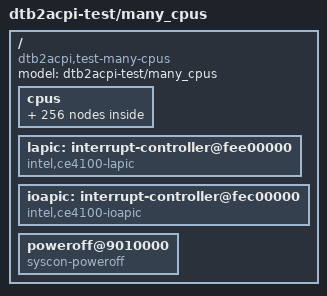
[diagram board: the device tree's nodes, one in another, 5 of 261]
/dts-v1/;

/* GENERATED by generate_many_cpus.sh — do not edit by hand. */

/ {
	#address-cells = <2>;
	#size-cells = <2>;
	model = "dtb2acpi-test/many_cpus";
	compatible = "dtb2acpi,test-many-cpus";

	cpus {
		#address-cells = <1>;
		#size-cells = <0>;

		cpu@0 {
			device_type = "cpu";
			reg = <0x0>;
			compatible = "intel,x86";
		};

		cpu@1 {
			device_type = "cpu";
			reg = <0x1>;
			compatible = "intel,x86";
		};

		cpu@2 {
			device_type = "cpu";
			reg = <0x2>;
			compatible = "intel,x86";
		};

		cpu@3 {
			device_type = "cpu";
			reg = <0x3>;
			compatible = "intel,x86";
		};

		cpu@4 {
			device_type = "cpu";
			reg = <0x4>;
			compatible = "intel,x86";
		};

		cpu@5 {
			device_type = "cpu";
			reg = <0x5>;
			compatible = "intel,x86";
		};

		cpu@6 {
			device_type = "cpu";
			reg = <0x6>;
			compatible = "intel,x86";
		};

		cpu@7 {
			device_type = "cpu";
			reg = <0x7>;
			compatible = "intel,x86";
		};

		cpu@8 {
			device_type = "cpu";
			reg = <0x8>;
			compatible = "intel,x86";
		};

		cpu@9 {
			device_type = "cpu";
			reg = <0x9>;
			compatible = "intel,x86";
		};

		cpu@a {
			device_type = "cpu";
			reg = <0xa>;
			compatible = "intel,x86";
		};

		cpu@b {
			device_type = "cpu";
			reg = <0xb>;
			compatible = "intel,x86";
		};

		cpu@c {
			device_type = "cpu";
			reg = <0xc>;
			compatible = "intel,x86";
		};

		cpu@d {
			device_type = "cpu";
			reg = <0xd>;
			compatible = "intel,x86";
		};

		cpu@e {
			device_type = "cpu";
			reg = <0xe>;
			compatible = "intel,x86";
		};

		cpu@f {
			device_type = "cpu";
			reg = <0xf>;
			compatible = "intel,x86";
		};

		cpu@10 {
			device_type = "cpu";
			reg = <0x10>;
			compatible = "intel,x86";
		};

		cpu@11 {
			device_type = "cpu";
			reg = <0x11>;
			compatible = "intel,x86";
		};

		cpu@12 {
			device_type = "cpu";
			reg = <0x12>;
			compatible = "intel,x86";
		};

		cpu@13 {
			device_type = "cpu";
			reg = <0x13>;
			compatible = "intel,x86";
		};

		cpu@14 {
			device_type = "cpu";
			reg = <0x14>;
			compatible = "intel,x86";
		};

		cpu@15 {
			device_type = "cpu";
			reg = <0x15>;
			compatible = "intel,x86";
		};

		cpu@16 {
			device_type = "cpu";
			reg = <0x16>;
			compatible = "intel,x86";
		};

		cpu@17 {
			device_type = "cpu";
			reg = <0x17>;
			compatible = "intel,x86";
		};

		cpu@18 {
			device_type = "cpu";
			reg = <0x18>;
			compatible = "intel,x86";
		};

		cpu@19 {
			device_type = "cpu";
			reg = <0x19>;
			compatible = "intel,x86";
		};

		cpu@1a {
			device_type = "cpu";
			reg = <0x1a>;
			compatible = "intel,x86";
		};

		cpu@1b {
			device_type = "cpu";
			reg = <0x1b>;
			compatible = "intel,x86";
		};

		cpu@1c {
			device_type = "cpu";
			reg = <0x1c>;
			compatible = "intel,x86";
		};

		cpu@1d {
			device_type = "cpu";
			reg = <0x1d>;
			compatible = "intel,x86";
		};

		cpu@1e {
			device_type = "cpu";
			reg = <0x1e>;
			compatible = "intel,x86";
		};

		cpu@1f {
			device_type = "cpu";
			reg = <0x1f>;
			compatible = "intel,x86";
		};

		cpu@20 {
			device_type = "cpu";
			reg = <0x20>;
			compatible = "intel,x86";
		};

		cpu@21 {
			device_type = "cpu";
			reg = <0x21>;
			compatible = "intel,x86";
		};

		cpu@22 {
			device_type = "cpu";
			reg = <0x22>;
			compatible = "intel,x86";
		};

		cpu@23 {
			device_type = "cpu";
			reg = <0x23>;
			compatible = "intel,x86";
		};

		cpu@24 {
			device_type = "cpu";
			reg = <0x24>;
			compatible = "intel,x86";
		};

		cpu@25 {
			device_type = "cpu";
			reg = <0x25>;
			compatible = "intel,x86";
		};

		cpu@26 {
			device_type = "cpu";
			reg = <0x26>;
			compatible = "intel,x86";
		};

		cpu@27 {
			device_type = "cpu";
			reg = <0x27>;
			compatible = "intel,x86";
		};

		cpu@28 {
			device_type = "cpu";
			reg = <0x28>;
			compatible = "intel,x86";
		};

		cpu@29 {
			device_type = "cpu";
			reg = <0x29>;
			compatible = "intel,x86";
		};

		cpu@2a {
			device_type = "cpu";
			reg = <0x2a>;
			compatible = "intel,x86";
		};

		cpu@2b {
			device_type = "cpu";
			reg = <0x2b>;
			compatible = "intel,x86";
		};

		cpu@2c {
			device_type = "cpu";
			reg = <0x2c>;
			compatible = "intel,x86";
		};

		cpu@2d {
			device_type = "cpu";
			reg = <0x2d>;
			compatible = "intel,x86";
		};

		cpu@2e {
			device_type = "cpu";
			reg = <0x2e>;
			compatible = "intel,x86";
		};

		cpu@2f {
			device_type = "cpu";
			reg = <0x2f>;
			compatible = "intel,x86";
		};

		cpu@30 {
			device_type = "cpu";
			reg = <0x30>;
			compatible = "intel,x86";
		};

		cpu@31 {
			device_type = "cpu";
			reg = <0x31>;
			compatible = "intel,x86";
		};

		cpu@32 {
			device_type = "cpu";
			reg = <0x32>;
			compatible = "intel,x86";
		};

		cpu@33 {
			device_type = "cpu";
			reg = <0x33>;
			compatible = "intel,x86";
		};

		cpu@34 {
			device_type = "cpu";
			reg = <0x34>;
			compatible = "intel,x86";
		};

		cpu@35 {
			device_type = "cpu";
			reg = <0x35>;
			compatible = "intel,x86";
		};

		cpu@36 {
			device_type = "cpu";
			reg = <0x36>;
			compatible = "intel,x86";
		};

		cpu@37 {
			device_type = "cpu";
			reg = <0x37>;
			compatible = "intel,x86";
		};

		cpu@38 {
			device_type = "cpu";
			reg = <0x38>;
			compatible = "intel,x86";
		};

		cpu@39 {
			device_type = "cpu";
			reg = <0x39>;
			compatible = "intel,x86";
		};

		cpu@3a {
			device_type = "cpu";
			reg = <0x3a>;
			compatible = "intel,x86";
		};

		cpu@3b {
			device_type = "cpu";
			reg = <0x3b>;
			compatible = "intel,x86";
		};

		cpu@3c {
			device_type = "cpu";
			reg = <0x3c>;
			compatible = "intel,x86";
		};

		cpu@3d {
			device_type = "cpu";
			reg = <0x3d>;
			compatible = "intel,x86";
		};

		cpu@3e {
			device_type = "cpu";
			reg = <0x3e>;
			compatible = "intel,x86";
		};

		cpu@3f {
			device_type = "cpu";
			reg = <0x3f>;
			compatible = "intel,x86";
		};

		cpu@40 {
			device_type = "cpu";
			reg = <0x40>;
			compatible = "intel,x86";
		};

		cpu@41 {
			device_type = "cpu";
			reg = <0x41>;
			compatible = "intel,x86";
		};

		cpu@42 {
			device_type = "cpu";
			reg = <0x42>;
			compatible = "intel,x86";
		};

		cpu@43 {
			device_type = "cpu";
			reg = <0x43>;
			compatible = "intel,x86";
		};

		cpu@44 {
			device_type = "cpu";
			reg = <0x44>;
			compatible = "intel,x86";
		};

		cpu@45 {
			device_type = "cpu";
			reg = <0x45>;
			compatible = "intel,x86";
		};

		cpu@46 {
			device_type = "cpu";
			reg = <0x46>;
			compatible = "intel,x86";
		};

		cpu@47 {
			device_type = "cpu";
			reg = <0x47>;
			compatible = "intel,x86";
		};

		cpu@48 {
			device_type = "cpu";
			reg = <0x48>;
			compatible = "intel,x86";
		};

		cpu@49 {
			device_type = "cpu";
			reg = <0x49>;
			compatible = "intel,x86";
		};

		cpu@4a {
			device_type = "cpu";
			reg = <0x4a>;
			compatible = "intel,x86";
		};

		cpu@4b {
			device_type = "cpu";
			reg = <0x4b>;
			compatible = "intel,x86";
		};

		cpu@4c {
			device_type = "cpu";
			reg = <0x4c>;
			compatible = "intel,x86";
		};

		cpu@4d {
			device_type = "cpu";
			reg = <0x4d>;
			compatible = "intel,x86";
		};

		cpu@4e {
			device_type = "cpu";
			reg = <0x4e>;
			compatible = "intel,x86";
		};

		cpu@4f {
			device_type = "cpu";
			reg = <0x4f>;
			compatible = "intel,x86";
		};

		cpu@50 {
			device_type = "cpu";
			reg = <0x50>;
			compatible = "intel,x86";
		};

		cpu@51 {
			device_type = "cpu";
			reg = <0x51>;
			compatible = "intel,x86";
		};

		cpu@52 {
			device_type = "cpu";
			reg = <0x52>;
			compatible = "intel,x86";
		};

		cpu@53 {
			device_type = "cpu";
			reg = <0x53>;
			compatible = "intel,x86";
		};

		cpu@54 {
			device_type = "cpu";
			reg = <0x54>;
			compatible = "intel,x86";
		};

		cpu@55 {
			device_type = "cpu";
			reg = <0x55>;
			compatible = "intel,x86";
		};

		cpu@56 {
			device_type = "cpu";
			reg = <0x56>;
			compatible = "intel,x86";
		};

		cpu@57 {
			device_type = "cpu";
			reg = <0x57>;
			compatible = "intel,x86";
		};

		cpu@58 {
			device_type = "cpu";
			reg = <0x58>;
			compatible = "intel,x86";
		};

		cpu@59 {
			device_type = "cpu";
			reg = <0x59>;
			compatible = "intel,x86";
		};

		cpu@5a {
			device_type = "cpu";
			reg = <0x5a>;
			compatible = "intel,x86";
		};

		cpu@5b {
			device_type = "cpu";
			reg = <0x5b>;
			compatible = "intel,x86";
		};

		cpu@5c {
			device_type = "cpu";
			reg = <0x5c>;
			compatible = "intel,x86";
		};

		cpu@5d {
			device_type = "cpu";
			reg = <0x5d>;
			compatible = "intel,x86";
		};

		cpu@5e {
			device_type = "cpu";
			reg = <0x5e>;
			compatible = "intel,x86";
		};

		cpu@5f {
			device_type = "cpu";
			reg = <0x5f>;
			compatible = "intel,x86";
		};

		cpu@60 {
			device_type = "cpu";
			reg = <0x60>;
			compatible = "intel,x86";
		};

		cpu@61 {
			device_type = "cpu";
			reg = <0x61>;
			compatible = "intel,x86";
		};

		cpu@62 {
			device_type = "cpu";
			reg = <0x62>;
			compatible = "intel,x86";
		};

		cpu@63 {
			device_type = "cpu";
			reg = <0x63>;
			compatible = "intel,x86";
		};

		cpu@64 {
			device_type = "cpu";
			reg = <0x64>;
			compatible = "intel,x86";
		};

		cpu@65 {
			device_type = "cpu";
			reg = <0x65>;
			compatible = "intel,x86";
		};

		cpu@66 {
			device_type = "cpu";
			reg = <0x66>;
			compatible = "intel,x86";
		};

		cpu@67 {
			device_type = "cpu";
			reg = <0x67>;
			compatible = "intel,x86";
		};

		cpu@68 {
			device_type = "cpu";
			reg = <0x68>;
			compatible = "intel,x86";
		};

		cpu@69 {
			device_type = "cpu";
			reg = <0x69>;
			compatible = "intel,x86";
		};

		cpu@6a {
			device_type = "cpu";
			reg = <0x6a>;
			compatible = "intel,x86";
		};

		cpu@6b {
			device_type = "cpu";
			reg = <0x6b>;
			compatible = "intel,x86";
		};

		cpu@6c {
			device_type = "cpu";
			reg = <0x6c>;
			compatible = "intel,x86";
		};

		cpu@6d {
			device_type = "cpu";
			reg = <0x6d>;
			compatible = "intel,x86";
		};

		cpu@6e {
			device_type = "cpu";
			reg = <0x6e>;
			compatible = "intel,x86";
		};

		cpu@6f {
			device_type = "cpu";
			reg = <0x6f>;
			compatible = "intel,x86";
		};

		cpu@70 {
			device_type = "cpu";
			reg = <0x70>;
			compatible = "intel,x86";
		};

		cpu@71 {
			device_type = "cpu";
			reg = <0x71>;
			compatible = "intel,x86";
		};

		cpu@72 {
			device_type = "cpu";
			reg = <0x72>;
			compatible = "intel,x86";
		};

		cpu@73 {
			device_type = "cpu";
			reg = <0x73>;
			compatible = "intel,x86";
		};

		cpu@74 {
			device_type = "cpu";
			reg = <0x74>;
			compatible = "intel,x86";
		};

		cpu@75 {
			device_type = "cpu";
			reg = <0x75>;
			compatible = "intel,x86";
		};

		cpu@76 {
			device_type = "cpu";
			reg = <0x76>;
			compatible = "intel,x86";
		};

		cpu@77 {
			device_type = "cpu";
			reg = <0x77>;
			compatible = "intel,x86";
		};

		cpu@78 {
			device_type = "cpu";
			reg = <0x78>;
			compatible = "intel,x86";
		};

		cpu@79 {
			device_type = "cpu";
			reg = <0x79>;
			compatible = "intel,x86";
		};

		cpu@7a {
			device_type = "cpu";
			reg = <0x7a>;
			compatible = "intel,x86";
		};

		cpu@7b {
			device_type = "cpu";
			reg = <0x7b>;
			compatible = "intel,x86";
		};

		cpu@7c {
			device_type = "cpu";
			reg = <0x7c>;
			compatible = "intel,x86";
		};

		cpu@7d {
			device_type = "cpu";
			reg = <0x7d>;
			compatible = "intel,x86";
		};

		cpu@7e {
			device_type = "cpu";
			reg = <0x7e>;
			compatible = "intel,x86";
		};

		cpu@7f {
			device_type = "cpu";
			reg = <0x7f>;
			compatible = "intel,x86";
		};

		cpu@80 {
			device_type = "cpu";
			reg = <0x80>;
			compatible = "intel,x86";
		};

		cpu@81 {
			device_type = "cpu";
			reg = <0x81>;
			compatible = "intel,x86";
		};

		cpu@82 {
			device_type = "cpu";
			reg = <0x82>;
			compatible = "intel,x86";
		};

		cpu@83 {
			device_type = "cpu";
			reg = <0x83>;
			compatible = "intel,x86";
		};

		cpu@84 {
			device_type = "cpu";
			reg = <0x84>;
			compatible = "intel,x86";
		};

		cpu@85 {
			device_type = "cpu";
			reg = <0x85>;
			compatible = "intel,x86";
		};

		cpu@86 {
			device_type = "cpu";
			reg = <0x86>;
			compatible = "intel,x86";
		};

		cpu@87 {
			device_type = "cpu";
			reg = <0x87>;
			compatible = "intel,x86";
		};

		cpu@88 {
			device_type = "cpu";
			reg = <0x88>;
			compatible = "intel,x86";
		};

		cpu@89 {
			device_type = "cpu";
			reg = <0x89>;
			compatible = "intel,x86";
		};

		cpu@8a {
			device_type = "cpu";
			reg = <0x8a>;
			compatible = "intel,x86";
		};

		cpu@8b {
			device_type = "cpu";
			reg = <0x8b>;
			compatible = "intel,x86";
		};

		cpu@8c {
			device_type = "cpu";
			reg = <0x8c>;
			compatible = "intel,x86";
		};

		cpu@8d {
			device_type = "cpu";
			reg = <0x8d>;
			compatible = "intel,x86";
		};

		cpu@8e {
			device_type = "cpu";
			reg = <0x8e>;
			compatible = "intel,x86";
		};

		cpu@8f {
			device_type = "cpu";
			reg = <0x8f>;
			compatible = "intel,x86";
		};

		cpu@90 {
			device_type = "cpu";
			reg = <0x90>;
			compatible = "intel,x86";
		};

		cpu@91 {
			device_type = "cpu";
			reg = <0x91>;
			compatible = "intel,x86";
		};

		cpu@92 {
			device_type = "cpu";
			reg = <0x92>;
			compatible = "intel,x86";
		};

		cpu@93 {
			device_type = "cpu";
			reg = <0x93>;
			compatible = "intel,x86";
		};

		cpu@94 {
			device_type = "cpu";
			reg = <0x94>;
			compatible = "intel,x86";
		};

		cpu@95 {
			device_type = "cpu";
			reg = <0x95>;
			compatible = "intel,x86";
		};

		cpu@96 {
			device_type = "cpu";
			reg = <0x96>;
			compatible = "intel,x86";
		};

		cpu@97 {
			device_type = "cpu";
			reg = <0x97>;
			compatible = "intel,x86";
		};

		cpu@98 {
			device_type = "cpu";
			reg = <0x98>;
			compatible = "intel,x86";
		};

		cpu@99 {
			device_type = "cpu";
			reg = <0x99>;
			compatible = "intel,x86";
		};

		cpu@9a {
			device_type = "cpu";
			reg = <0x9a>;
			compatible = "intel,x86";
		};

		cpu@9b {
			device_type = "cpu";
			reg = <0x9b>;
			compatible = "intel,x86";
		};

		cpu@9c {
			device_type = "cpu";
			reg = <0x9c>;
			compatible = "intel,x86";
		};

		cpu@9d {
			device_type = "cpu";
			reg = <0x9d>;
			compatible = "intel,x86";
		};

		cpu@9e {
			device_type = "cpu";
			reg = <0x9e>;
			compatible = "intel,x86";
		};

		cpu@9f {
			device_type = "cpu";
			reg = <0x9f>;
			compatible = "intel,x86";
		};

		cpu@a0 {
			device_type = "cpu";
			reg = <0xa0>;
			compatible = "intel,x86";
		};

		cpu@a1 {
			device_type = "cpu";
			reg = <0xa1>;
			compatible = "intel,x86";
		};

		cpu@a2 {
			device_type = "cpu";
			reg = <0xa2>;
			compatible = "intel,x86";
		};

		cpu@a3 {
			device_type = "cpu";
			reg = <0xa3>;
			compatible = "intel,x86";
		};

		cpu@a4 {
			device_type = "cpu";
			reg = <0xa4>;
			compatible = "intel,x86";
		};

		cpu@a5 {
			device_type = "cpu";
			reg = <0xa5>;
			compatible = "intel,x86";
		};

		cpu@a6 {
			device_type = "cpu";
			reg = <0xa6>;
			compatible = "intel,x86";
		};

		cpu@a7 {
			device_type = "cpu";
			reg = <0xa7>;
			compatible = "intel,x86";
		};

		cpu@a8 {
			device_type = "cpu";
			reg = <0xa8>;
			compatible = "intel,x86";
		};

		cpu@a9 {
			device_type = "cpu";
			reg = <0xa9>;
			compatible = "intel,x86";
		};

		cpu@aa {
			device_type = "cpu";
			reg = <0xaa>;
			compatible = "intel,x86";
		};

		cpu@ab {
			device_type = "cpu";
			reg = <0xab>;
			compatible = "intel,x86";
		};

		cpu@ac {
			device_type = "cpu";
			reg = <0xac>;
			compatible = "intel,x86";
		};

		cpu@ad {
			device_type = "cpu";
			reg = <0xad>;
			compatible = "intel,x86";
		};

		cpu@ae {
			device_type = "cpu";
			reg = <0xae>;
			compatible = "intel,x86";
		};

		cpu@af {
			device_type = "cpu";
			reg = <0xaf>;
			compatible = "intel,x86";
		};

		cpu@b0 {
			device_type = "cpu";
			reg = <0xb0>;
			compatible = "intel,x86";
		};

		cpu@b1 {
			device_type = "cpu";
			reg = <0xb1>;
			compatible = "intel,x86";
		};

		cpu@b2 {
			device_type = "cpu";
			reg = <0xb2>;
			compatible = "intel,x86";
		};

		cpu@b3 {
			device_type = "cpu";
			reg = <0xb3>;
			compatible = "intel,x86";
		};

		cpu@b4 {
			device_type = "cpu";
			reg = <0xb4>;
			compatible = "intel,x86";
		};

		cpu@b5 {
			device_type = "cpu";
			reg = <0xb5>;
			compatible = "intel,x86";
		};

		cpu@b6 {
			device_type = "cpu";
			reg = <0xb6>;
			compatible = "intel,x86";
		};

		cpu@b7 {
			device_type = "cpu";
			reg = <0xb7>;
			compatible = "intel,x86";
		};

		cpu@b8 {
			device_type = "cpu";
			reg = <0xb8>;
			compatible = "intel,x86";
		};

		cpu@b9 {
			device_type = "cpu";
			reg = <0xb9>;
			compatible = "intel,x86";
		};

		cpu@ba {
			device_type = "cpu";
			reg = <0xba>;
			compatible = "intel,x86";
		};

		cpu@bb {
			device_type = "cpu";
			reg = <0xbb>;
			compatible = "intel,x86";
		};

		cpu@bc {
			device_type = "cpu";
			reg = <0xbc>;
			compatible = "intel,x86";
		};

		cpu@bd {
			device_type = "cpu";
			reg = <0xbd>;
			compatible = "intel,x86";
		};

		cpu@be {
			device_type = "cpu";
			reg = <0xbe>;
			compatible = "intel,x86";
		};

		cpu@bf {
			device_type = "cpu";
			reg = <0xbf>;
			compatible = "intel,x86";
		};

		cpu@c0 {
			device_type = "cpu";
			reg = <0xc0>;
			compatible = "intel,x86";
		};

		cpu@c1 {
			device_type = "cpu";
			reg = <0xc1>;
			compatible = "intel,x86";
		};

		cpu@c2 {
			device_type = "cpu";
			reg = <0xc2>;
			compatible = "intel,x86";
		};

		cpu@c3 {
			device_type = "cpu";
			reg = <0xc3>;
			compatible = "intel,x86";
		};

		cpu@c4 {
			device_type = "cpu";
			reg = <0xc4>;
			compatible = "intel,x86";
		};

		cpu@c5 {
			device_type = "cpu";
			reg = <0xc5>;
			compatible = "intel,x86";
		};

		cpu@c6 {
			device_type = "cpu";
			reg = <0xc6>;
			compatible = "intel,x86";
		};

		cpu@c7 {
			device_type = "cpu";
			reg = <0xc7>;
			compatible = "intel,x86";
		};

		cpu@c8 {
			device_type = "cpu";
			reg = <0xc8>;
			compatible = "intel,x86";
		};

		cpu@c9 {
			device_type = "cpu";
			reg = <0xc9>;
			compatible = "intel,x86";
		};

		cpu@ca {
			device_type = "cpu";
			reg = <0xca>;
			compatible = "intel,x86";
		};

		cpu@cb {
			device_type = "cpu";
			reg = <0xcb>;
			compatible = "intel,x86";
		};

		cpu@cc {
			device_type = "cpu";
			reg = <0xcc>;
			compatible = "intel,x86";
		};

		cpu@cd {
			device_type = "cpu";
			reg = <0xcd>;
			compatible = "intel,x86";
		};

		cpu@ce {
			device_type = "cpu";
			reg = <0xce>;
			compatible = "intel,x86";
		};

		cpu@cf {
			device_type = "cpu";
			reg = <0xcf>;
			compatible = "intel,x86";
		};

		cpu@d0 {
			device_type = "cpu";
			reg = <0xd0>;
			compatible = "intel,x86";
		};

		cpu@d1 {
			device_type = "cpu";
			reg = <0xd1>;
			compatible = "intel,x86";
		};

		cpu@d2 {
			device_type = "cpu";
			reg = <0xd2>;
			compatible = "intel,x86";
		};

		cpu@d3 {
			device_type = "cpu";
			reg = <0xd3>;
			compatible = "intel,x86";
		};

		cpu@d4 {
			device_type = "cpu";
			reg = <0xd4>;
			compatible = "intel,x86";
		};

		cpu@d5 {
			device_type = "cpu";
			reg = <0xd5>;
			compatible = "intel,x86";
		};

		cpu@d6 {
			device_type = "cpu";
			reg = <0xd6>;
			compatible = "intel,x86";
		};

		cpu@d7 {
			device_type = "cpu";
			reg = <0xd7>;
			compatible = "intel,x86";
		};

		cpu@d8 {
			device_type = "cpu";
			reg = <0xd8>;
			compatible = "intel,x86";
		};

		cpu@d9 {
			device_type = "cpu";
			reg = <0xd9>;
			compatible = "intel,x86";
		};

		cpu@da {
			device_type = "cpu";
			reg = <0xda>;
			compatible = "intel,x86";
		};

		cpu@db {
			device_type = "cpu";
			reg = <0xdb>;
			compatible = "intel,x86";
		};

		cpu@dc {
			device_type = "cpu";
			reg = <0xdc>;
			compatible = "intel,x86";
		};

		cpu@dd {
			device_type = "cpu";
			reg = <0xdd>;
			compatible = "intel,x86";
		};

		cpu@de {
			device_type = "cpu";
			reg = <0xde>;
			compatible = "intel,x86";
		};

		cpu@df {
			device_type = "cpu";
			reg = <0xdf>;
			compatible = "intel,x86";
		};

		cpu@e0 {
			device_type = "cpu";
			reg = <0xe0>;
			compatible = "intel,x86";
		};

		cpu@e1 {
			device_type = "cpu";
			reg = <0xe1>;
			compatible = "intel,x86";
		};

		cpu@e2 {
			device_type = "cpu";
			reg = <0xe2>;
			compatible = "intel,x86";
		};

		cpu@e3 {
			device_type = "cpu";
			reg = <0xe3>;
			compatible = "intel,x86";
		};

		cpu@e4 {
			device_type = "cpu";
			reg = <0xe4>;
			compatible = "intel,x86";
		};

		cpu@e5 {
			device_type = "cpu";
			reg = <0xe5>;
			compatible = "intel,x86";
		};

		cpu@e6 {
			device_type = "cpu";
			reg = <0xe6>;
			compatible = "intel,x86";
		};

		cpu@e7 {
			device_type = "cpu";
			reg = <0xe7>;
			compatible = "intel,x86";
		};

		cpu@e8 {
			device_type = "cpu";
			reg = <0xe8>;
			compatible = "intel,x86";
		};

		cpu@e9 {
			device_type = "cpu";
			reg = <0xe9>;
			compatible = "intel,x86";
		};

		cpu@ea {
			device_type = "cpu";
			reg = <0xea>;
			compatible = "intel,x86";
		};

		cpu@eb {
			device_type = "cpu";
			reg = <0xeb>;
			compatible = "intel,x86";
		};

		cpu@ec {
			device_type = "cpu";
			reg = <0xec>;
			compatible = "intel,x86";
		};

		cpu@ed {
			device_type = "cpu";
			reg = <0xed>;
			compatible = "intel,x86";
		};

		cpu@ee {
			device_type = "cpu";
			reg = <0xee>;
			compatible = "intel,x86";
		};

		cpu@ef {
			device_type = "cpu";
			reg = <0xef>;
			compatible = "intel,x86";
		};

		cpu@f0 {
			device_type = "cpu";
			reg = <0xf0>;
			compatible = "intel,x86";
		};

		cpu@f1 {
			device_type = "cpu";
			reg = <0xf1>;
			compatible = "intel,x86";
		};

		cpu@f2 {
			device_type = "cpu";
			reg = <0xf2>;
			compatible = "intel,x86";
		};

		cpu@f3 {
			device_type = "cpu";
			reg = <0xf3>;
			compatible = "intel,x86";
		};

		cpu@f4 {
			device_type = "cpu";
			reg = <0xf4>;
			compatible = "intel,x86";
		};

		cpu@f5 {
			device_type = "cpu";
			reg = <0xf5>;
			compatible = "intel,x86";
		};

		cpu@f6 {
			device_type = "cpu";
			reg = <0xf6>;
			compatible = "intel,x86";
		};

		cpu@f7 {
			device_type = "cpu";
			reg = <0xf7>;
			compatible = "intel,x86";
		};

		cpu@f8 {
			device_type = "cpu";
			reg = <0xf8>;
			compatible = "intel,x86";
		};

		cpu@f9 {
			device_type = "cpu";
			reg = <0xf9>;
			compatible = "intel,x86";
		};

		cpu@fa {
			device_type = "cpu";
			reg = <0xfa>;
			compatible = "intel,x86";
		};

		cpu@fb {
			device_type = "cpu";
			reg = <0xfb>;
			compatible = "intel,x86";
		};

		cpu@fc {
			device_type = "cpu";
			reg = <0xfc>;
			compatible = "intel,x86";
		};

		cpu@fd {
			device_type = "cpu";
			reg = <0xfd>;
			compatible = "intel,x86";
		};

		cpu@fe {
			device_type = "cpu";
			reg = <0xfe>;
			compatible = "intel,x86";
		};

		cpu@ff {
			device_type = "cpu";
			reg = <0xff>;
			compatible = "intel,x86";
		};

	};

	lapic: interrupt-controller@fee00000 {
		compatible = "intel,ce4100-lapic";
		reg = <0x0 0xfee00000 0x0 0x1000>;
		interrupt-controller;
		#interrupt-cells = <2>;
	};

	ioapic: interrupt-controller@fec00000 {
		compatible = "intel,ce4100-ioapic";
		reg = <0x0 0xfec00000 0x0 0x1000>;
		interrupt-controller;
		#interrupt-cells = <2>;
	};

	poweroff@9010000 {
		compatible = "syscon-poweroff";
		reg = <0x0 0x9010000 0x0 0x4>;
		value = <0x34>;
	};
};
